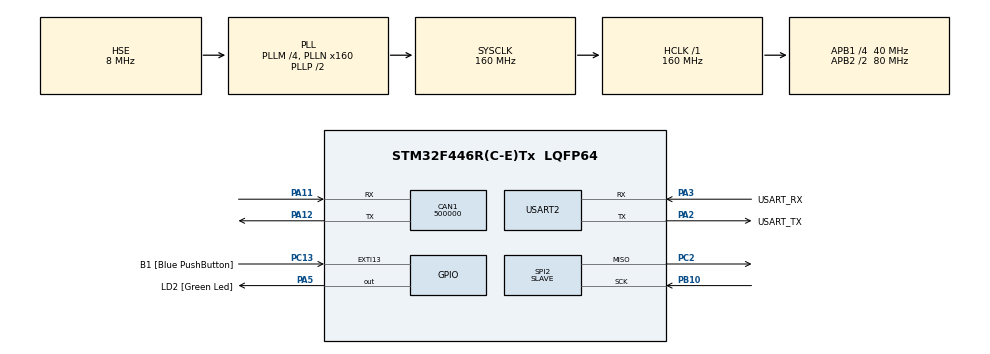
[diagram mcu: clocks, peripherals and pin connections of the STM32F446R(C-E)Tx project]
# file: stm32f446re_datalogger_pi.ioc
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CAN1.BS1=CAN_BS1_3TQ
CAN1.CalculateBaudRate=500000
CAN1.CalculateTimeBit=2000
CAN1.CalculateTimeQuantum=400.0
CAN1.Mode=CAN_MODE_NORMAL
Dma.Request0=USART2_TX
Dma.Request1=SPI2_TX
Dma.SPI2_TX.1.Direction=DMA_MEMORY_TO_PERIPH
Dma.SPI2_TX.1.FIFOMode=DMA_FIFOMODE_ENABLE
Dma.SPI2_TX.1.FIFOThreshold=DMA_FIFO_THRESHOLD_FULL
Dma.SPI2_TX.1.Instance=DMA1_Stream4
Dma.SPI2_TX.1.MemBurst=DMA_MBURST_SINGLE
Dma.SPI2_TX.1.MemDataAlignment=DMA_MDATAALIGN_BYTE
Dma.SPI2_TX.1.MemInc=DMA_MINC_ENABLE
Dma.SPI2_TX.1.Mode=DMA_NORMAL
Dma.SPI2_TX.1.PeriphBurst=DMA_PBURST_SINGLE
Dma.SPI2_TX.1.PeriphDataAlignment=DMA_PDATAALIGN_BYTE
Dma.SPI2_TX.1.PeriphInc=DMA_PINC_DISABLE
Dma.SPI2_TX.1.Priority=DMA_PRIORITY_LOW
Dma.USART2_TX.0.Direction=DMA_MEMORY_TO_PERIPH
Dma.USART2_TX.0.FIFOMode=DMA_FIFOMODE_ENABLE
Dma.USART2_TX.0.FIFOThreshold=DMA_FIFO_THRESHOLD_FULL
Dma.USART2_TX.0.Instance=DMA1_Stream6
Dma.USART2_TX.0.MemBurst=DMA_MBURST_SINGLE
Dma.USART2_TX.0.MemDataAlignment=DMA_MDATAALIGN_BYTE
Dma.USART2_TX.0.MemInc=DMA_MINC_ENABLE
Dma.USART2_TX.0.Mode=DMA_NORMAL
Dma.USART2_TX.0.PeriphBurst=DMA_PBURST_SINGLE
Dma.USART2_TX.0.PeriphDataAlignment=DMA_PDATAALIGN_BYTE
Dma.USART2_TX.0.PeriphInc=DMA_PINC_DISABLE
Dma.USART2_TX.0.Priority=DMA_PRIORITY_LOW
Mcu.Family=STM32F4
Mcu.Name=STM32F446R(C-E)Tx
Mcu.Package=LQFP64
NVIC.CAN1_RX0_IRQn=true\:0\:0\:false\:false\:true\:true\:true\:true
NVIC.CAN1_RX1_IRQn=true\:0\:0\:false\:false\:true\:true\:true\:true
NVIC.DMA1_Stream4_IRQn=true\:0\:0\:false\:false\:true\:false\:true\:true
NVIC.DMA1_Stream6_IRQn=true\:0\:0\:false\:false\:true\:false\:true\:true
NVIC.PriorityGroup=NVIC_PRIORITYGROUP_0
PA11.Mode=CAN_Activate
PA11.Signal=CAN1_RX
PA12.Mode=CAN_Activate
PA12.Signal=CAN1_TX
PA13.GPIO_Label=TMS
PA13.Mode=Serial_Wire
PA13.Signal=SYS_JTMS-SWDIO
PA14.GPIO_Label=TCK
PA14.Mode=Serial_Wire
PA14.Signal=SYS_JTCK-SWCLK
PA2.GPIO_Label=USART_TX
PA2.Mode=Asynchronous
PA2.Signal=USART2_TX
PA3.GPIO_Label=USART_RX
PA3.Mode=Asynchronous
PA3.Signal=USART2_RX
PA5.GPIO_Label=LD2 [Green Led]
PA5.Signal=GPIO_Output
PB10.Mode=TX_Only_Simplex_Unidirect_Slave
PB10.Signal=SPI2_SCK
PB3.GPIO_Label=SWO
PB3.Signal=SYS_JTDO-SWO
PC13.GPIO_Label=B1 [Blue PushButton]
PC13.GPIO_ModeDefaultEXTI=GPIO_MODE_IT_FALLING
PC13.Signal=GPXTI13
PC14-OSC32_IN.Mode=LSE-External-Oscillator
PC14-OSC32_IN.Signal=RCC_OSC32_IN
PC15-OSC32_OUT.Mode=LSE-External-Oscillator
PC15-OSC32_OUT.Signal=RCC_OSC32_OUT
PC2.Mode=TX_Only_Simplex_Unidirect_Slave
PC2.Signal=SPI2_MISO
PH0-OSC_IN.Mode=HSE-External-Oscillator
PH0-OSC_IN.Signal=RCC_OSC_IN
PH1-OSC_OUT.Mode=HSE-External-Oscillator
PH1-OSC_OUT.Signal=RCC_OSC_OUT
ProjectManager.HeapSize=0x200
ProjectManager.StackSize=0x400
ProjectManager.TargetToolchain=STM32CubeIDE
RCC.48MHZClocksFreq_Value=84000000
RCC.AHBFreq_Value=160000000
RCC.APB1CLKDivider=RCC_HCLK_DIV4
RCC.APB1Freq_Value=40000000
RCC.APB1TimFreq_Value=80000000
RCC.APB2CLKDivider=RCC_HCLK_DIV2
RCC.APB2Freq_Value=80000000
RCC.APB2TimFreq_Value=160000000
RCC.CortexFreq_Value=160000000
RCC.FLatency-AdvancedSettings=FLASH_LATENCY_5
RCC.HCLKFreq_Value=160000000
RCC.HSE_VALUE=8000000
RCC.HSI_VALUE=16000000
RCC.PLLM=4
RCC.PLLN=160
RCC.PLLSourceVirtual=RCC_PLLSOURCE_HSE
RCC.SYSCLKFreq_VALUE=160000000
RCC.SYSCLKSource=RCC_SYSCLKSOURCE_PLLCLK
RCC.USBFreq_Value=160000000
RCC.VCOOutputFreq_Value=320000000
SPI2.Direction=SPI_DIRECTION_2LINES
SPI2.Mode=SPI_MODE_SLAVE
SPI2.VirtualType=VM_SLAVE
USART2.VirtualMode=VM_ASYNC
board=NUCLEO-F446RE

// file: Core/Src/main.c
/* USER CODE BEGIN Header */
/**
  ******************************************************************************
  * @file           : main.c
  * @brief          : Main program body
  ******************************************************************************
  * @attention
  *
  * Copyright (c) 2023 STMicroelectronics.
  * All rights reserved.
  *
  * This software is licensed under terms that can be found in the LICENSE file
  * in the root directory of this software component.
  * If no LICENSE file comes with this software, it is provided AS-IS.
  *
  ******************************************************************************
  */
/* USER CODE END Header */
#include "main.h"

/* USER CODE BEGIN Includes */
#include "FEB_CAN.h"

/* USER CODE END Includes */

CAN_HandleTypeDef hcan1;

SPI_HandleTypeDef hspi2;
DMA_HandleTypeDef hdma_spi2_tx;

UART_HandleTypeDef huart2;
DMA_HandleTypeDef hdma_usart2_tx;

void SystemClock_Config(void);
static void MX_GPIO_Init(void);
static void MX_DMA_Init(void);
static void MX_USART2_UART_Init(void);
static void MX_CAN1_Init(void);
static void MX_SPI2_Init(void);

int main(void)
{

  /* MCU Configuration--------------------------------------------------------*/

  /* Reset of all peripherals, Initializes the Flash interface and the Systick. */
  HAL_Init();

  /* Configure the system clock */
  SystemClock_Config();

  /* Initialize all configured peripherals */
  MX_GPIO_Init();
  MX_DMA_Init();
  MX_USART2_UART_Init();
  MX_CAN1_Init();
  MX_SPI2_Init();
  /* USER CODE BEGIN 2 */
  uint16_t sleep_time = 0;
  float temp = 30.0;
  float volt = 200.0;
  float speed = 0.0;
  uint8_t ready_to_drive = 0;
  FEB_CAN_Init(&hcan1);

  /* USER CODE END 2 */

  /* Infinite loop */
  /* USER CODE BEGIN WHILE */
  while (1)
  {
//	  temp = temp + 0.01;
//	  FEB_CAN_Transmit(&hcan1, BMS_TEMPERATURE, &temp, sizeof(BMS_TEMPERATURE_TYPE));
//	  volt = volt + 0.02;
//	  FEB_CAN_Transmit(&hcan1, BMS_VOLTAGE, &volt, sizeof(BMS_VOLTAGE_TYPE));
//	  speed = speed + 3;
//	  FEB_CAN_Transmit(&hcan1, 0x0A5, &speed, sizeof(float));
//	  ready_to_drive = !ready_to_drive;
//	  FEB_CAN_Transmit(&hcan1, SW_READY_TO_DRIVE, &ready_to_drive, sizeof(SW_READY_TO_DRIVE_TYPE));
    /* USER CODE END WHILE */

    /* USER CODE BEGIN 3 */
//	  HAL_Delay(sleep_time);
  }
  /* USER CODE END 3 */
}

void SystemClock_Config(void)
{
  RCC_OscInitTypeDef RCC_OscInitStruct = {0};
  RCC_ClkInitTypeDef RCC_ClkInitStruct = {0};

  /** Configure the main internal regulator output voltage
  */
  __HAL_RCC_PWR_CLK_ENABLE();
  __HAL_PWR_VOLTAGESCALING_CONFIG(PWR_REGULATOR_VOLTAGE_SCALE1);

  /** Initializes the RCC Oscillators according to the specified parameters
  * in the RCC_OscInitTypeDef structure.
  */
  RCC_OscInitStruct.OscillatorType = RCC_OSCILLATORTYPE_HSE;
  RCC_OscInitStruct.HSEState = RCC_HSE_ON;
  RCC_OscInitStruct.PLL.PLLState = RCC_PLL_ON;
  RCC_OscInitStruct.PLL.PLLSource = RCC_PLLSOURCE_HSE;
  RCC_OscInitStruct.PLL.PLLM = 4;
  RCC_OscInitStruct.PLL.PLLN = 160;
  RCC_OscInitStruct.PLL.PLLP = RCC_PLLP_DIV2;
  RCC_OscInitStruct.PLL.PLLQ = 2;
  RCC_OscInitStruct.PLL.PLLR = 2;
  if (HAL_RCC_OscConfig(&RCC_OscInitStruct) != HAL_OK)
  {
    Error_Handler();
  }

  /** Initializes the CPU, AHB and APB buses clocks
  */
  RCC_ClkInitStruct.ClockType = RCC_CLOCKTYPE_HCLK|RCC_CLOCKTYPE_SYSCLK
                              |RCC_CLOCKTYPE_PCLK1|RCC_CLOCKTYPE_PCLK2;
  RCC_ClkInitStruct.SYSCLKSource = RCC_SYSCLKSOURCE_PLLCLK;
  RCC_ClkInitStruct.AHBCLKDivider = RCC_SYSCLK_DIV1;
  RCC_ClkInitStruct.APB1CLKDivider = RCC_HCLK_DIV4;
  RCC_ClkInitStruct.APB2CLKDivider = RCC_HCLK_DIV2;

  if (HAL_RCC_ClockConfig(&RCC_ClkInitStruct, FLASH_LATENCY_5) != HAL_OK)
  {
    Error_Handler();
  }
}

static void MX_CAN1_Init(void)
{

  hcan1.Instance = CAN1;
  hcan1.Init.Prescaler = 16;
  hcan1.Init.Mode = CAN_MODE_NORMAL;
  hcan1.Init.SyncJumpWidth = CAN_SJW_1TQ;
  hcan1.Init.TimeSeg1 = CAN_BS1_3TQ;
  hcan1.Init.TimeSeg2 = CAN_BS2_1TQ;
  hcan1.Init.TimeTriggeredMode = DISABLE;
  hcan1.Init.AutoBusOff = DISABLE;
  hcan1.Init.AutoWakeUp = DISABLE;
  hcan1.Init.AutoRetransmission = DISABLE;
  hcan1.Init.ReceiveFifoLocked = DISABLE;
  hcan1.Init.TransmitFifoPriority = DISABLE;
  if (HAL_CAN_Init(&hcan1) != HAL_OK)
  {
    Error_Handler();
  }

}

static void MX_SPI2_Init(void)
{

  /* SPI2 parameter configuration*/
  hspi2.Instance = SPI2;
  hspi2.Init.Mode = SPI_MODE_SLAVE;
  hspi2.Init.Direction = SPI_DIRECTION_2LINES;
  hspi2.Init.DataSize = SPI_DATASIZE_8BIT;
  hspi2.Init.CLKPolarity = SPI_POLARITY_LOW;
  hspi2.Init.CLKPhase = SPI_PHASE_1EDGE;
  hspi2.Init.NSS = SPI_NSS_SOFT;
  hspi2.Init.FirstBit = SPI_FIRSTBIT_MSB;
  hspi2.Init.TIMode = SPI_TIMODE_DISABLE;
  hspi2.Init.CRCCalculation = SPI_CRCCALCULATION_DISABLE;
  hspi2.Init.CRCPolynomial = 10;
  if (HAL_SPI_Init(&hspi2) != HAL_OK)
  {
    Error_Handler();
  }

}

static void MX_USART2_UART_Init(void)
{

  huart2.Instance = USART2;
  huart2.Init.BaudRate = 115200;
  huart2.Init.WordLength = UART_WORDLENGTH_8B;
  huart2.Init.StopBits = UART_STOPBITS_1;
  huart2.Init.Parity = UART_PARITY_NONE;
  huart2.Init.Mode = UART_MODE_TX_RX;
  huart2.Init.HwFlowCtl = UART_HWCONTROL_NONE;
  huart2.Init.OverSampling = UART_OVERSAMPLING_16;
  if (HAL_UART_Init(&huart2) != HAL_OK)
  {
    Error_Handler();
  }

}

static void MX_DMA_Init(void)
{

  /* DMA controller clock enable */
  __HAL_RCC_DMA1_CLK_ENABLE();

  /* DMA interrupt init */
  /* DMA1_Stream4_IRQn interrupt configuration */
  HAL_NVIC_SetPriority(DMA1_Stream4_IRQn, 0, 0);
  HAL_NVIC_EnableIRQ(DMA1_Stream4_IRQn);
  /* DMA1_Stream6_IRQn interrupt configuration */
  HAL_NVIC_SetPriority(DMA1_Stream6_IRQn, 0, 0);
  HAL_NVIC_EnableIRQ(DMA1_Stream6_IRQn);

}

static void MX_GPIO_Init(void)
{
  GPIO_InitTypeDef GPIO_InitStruct = {0};

  /* GPIO Ports Clock Enable */
  __HAL_RCC_GPIOC_CLK_ENABLE();
  __HAL_RCC_GPIOH_CLK_ENABLE();
  __HAL_RCC_GPIOA_CLK_ENABLE();
  __HAL_RCC_GPIOB_CLK_ENABLE();

  /*Configure GPIO pin Output Level */
  HAL_GPIO_WritePin(LD2_GPIO_Port, LD2_Pin, GPIO_PIN_RESET);

  /*Configure GPIO pin : B1_Pin */
  GPIO_InitStruct.Pin = B1_Pin;
  GPIO_InitStruct.Mode = GPIO_MODE_IT_FALLING;
  GPIO_InitStruct.Pull = GPIO_NOPULL;
  HAL_GPIO_Init(B1_GPIO_Port, &GPIO_InitStruct);

  /*Configure GPIO pin : LD2_Pin */
  GPIO_InitStruct.Pin = LD2_Pin;
  GPIO_InitStruct.Mode = GPIO_MODE_OUTPUT_PP;
  GPIO_InitStruct.Pull = GPIO_NOPULL;
  GPIO_InitStruct.Speed = GPIO_SPEED_FREQ_LOW;
  HAL_GPIO_Init(LD2_GPIO_Port, &GPIO_InitStruct);

}

void Error_Handler(void)
{
  __disable_irq();
  while (1)
  {
  }
}
